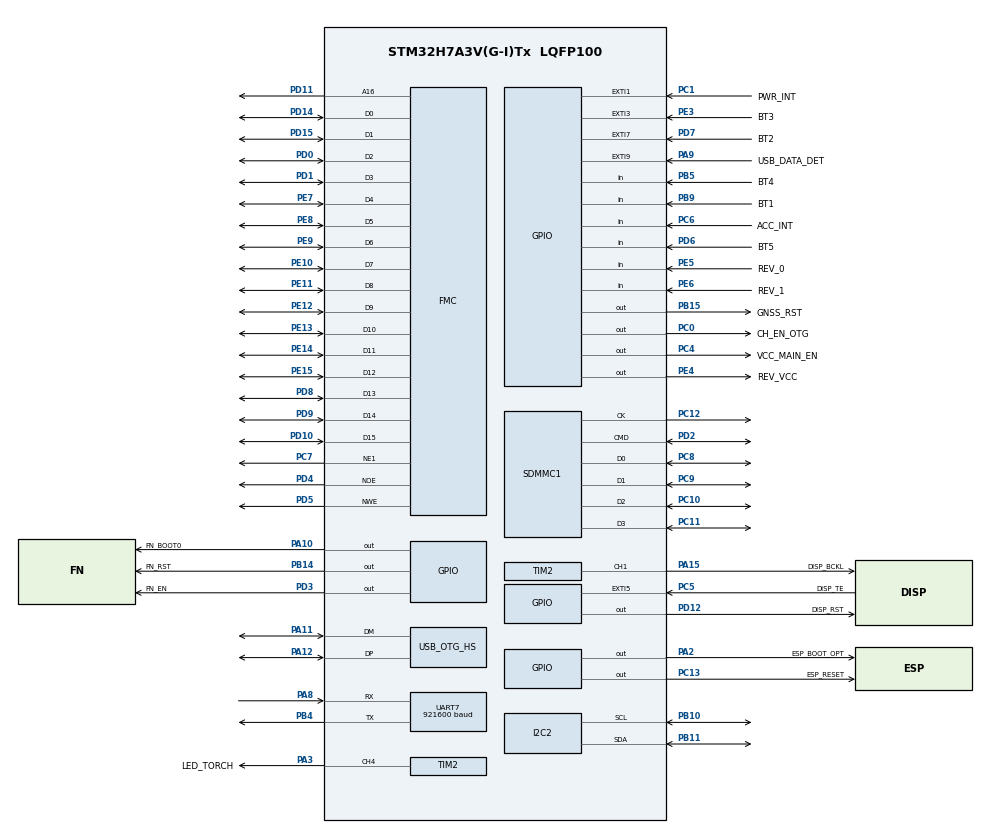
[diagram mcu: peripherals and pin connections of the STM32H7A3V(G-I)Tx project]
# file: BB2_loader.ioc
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CORTEX_M7.AccessPermission-Cortex_Memory_Protection_Unit_Region0_Settings=MPU_REGION_FULL_ACCESS
CORTEX_M7.CPU_DCache=Disabled
CORTEX_M7.Enable-Cortex_Memory_Protection_Unit_Region0_Settings=MPU_REGION_ENABLE
CORTEX_M7.MPU_Control=__NULL
CORTEX_M7.Size-Cortex_Memory_Protection_Unit_Region0_Settings=MPU_REGION_SIZE_4GB
CRC.InputDataInversionMode=CRC_INPUTDATA_INVERSION_BYTE
CRC.OutputDataInversionMode=CRC_OUTPUTDATA_INVERSION_ENABLE
Dma.MEMTOMEM.0.Direction=DMA_MEMORY_TO_MEMORY
Dma.MEMTOMEM.0.EventEnable=DISABLE
Dma.MEMTOMEM.0.FIFOMode=DMA_FIFOMODE_ENABLE
Dma.MEMTOMEM.0.FIFOThreshold=DMA_FIFO_THRESHOLD_FULL
Dma.MEMTOMEM.0.Instance=DMA1_Stream0
Dma.MEMTOMEM.0.MemBurst=DMA_MBURST_SINGLE
Dma.MEMTOMEM.0.MemDataAlignment=DMA_MDATAALIGN_WORD
Dma.MEMTOMEM.0.MemInc=DMA_MINC_DISABLE
Dma.MEMTOMEM.0.Mode=DMA_NORMAL
Dma.MEMTOMEM.0.PeriphBurst=DMA_PBURST_SINGLE
Dma.MEMTOMEM.0.PeriphDataAlignment=DMA_PDATAALIGN_WORD
Dma.MEMTOMEM.0.PeriphInc=DMA_PINC_ENABLE
Dma.MEMTOMEM.0.Polarity=HAL_DMAMUX_REQ_GEN_RISING
Dma.MEMTOMEM.0.Priority=DMA_PRIORITY_LOW
Dma.MEMTOMEM.0.RequestNumber=1
Dma.MEMTOMEM.0.SignalID=NONE
Dma.MEMTOMEM.0.SyncEnable=DISABLE
Dma.MEMTOMEM.0.SyncPolarity=HAL_DMAMUX_SYNC_NO_EVENT
Dma.MEMTOMEM.0.SyncRequestNumber=1
Dma.MEMTOMEM.0.SyncSignalID=NONE
Dma.Request0=MEMTOMEM
Dma.Request1=UART7_TX
Dma.UART7_TX.1.Direction=DMA_MEMORY_TO_PERIPH
Dma.UART7_TX.1.EventEnable=DISABLE
Dma.UART7_TX.1.FIFOMode=DMA_FIFOMODE_DISABLE
Dma.UART7_TX.1.Instance=DMA1_Stream1
Dma.UART7_TX.1.MemDataAlignment=DMA_MDATAALIGN_BYTE
Dma.UART7_TX.1.MemInc=DMA_MINC_ENABLE
Dma.UART7_TX.1.Mode=DMA_NORMAL
Dma.UART7_TX.1.PeriphDataAlignment=DMA_PDATAALIGN_BYTE
Dma.UART7_TX.1.PeriphInc=DMA_PINC_DISABLE
Dma.UART7_TX.1.Polarity=HAL_DMAMUX_REQ_GEN_RISING
Dma.UART7_TX.1.Priority=DMA_PRIORITY_MEDIUM
Dma.UART7_TX.1.RequestNumber=1
Dma.UART7_TX.1.SignalID=NONE
Dma.UART7_TX.1.SyncEnable=DISABLE
Dma.UART7_TX.1.SyncPolarity=HAL_DMAMUX_SYNC_NO_EVENT
Dma.UART7_TX.1.SyncRequestNumber=1
Dma.UART7_TX.1.SyncSignalID=NONE
FATFS.USE_DMA_CODE_SD=1
FATFS._USE_MKFS=0
FMC.AddressSetupTime1=6
FMC.BankMapConfig=FMC_SWAPBMAP_SDRAM_SRAM
FMC.BusTurnAroundDuration1=0
FMC.DataSetupTime1=12
I2C2.Timing=0x20B0CCFF
Mcu.Family=STM32H7
Mcu.Name=STM32H7A3V(G-I)Tx
Mcu.Package=LQFP100
Mcu.UserConstants=debug_uart,huart7;esp_uart,huart4;fanet_uart,huart8;gnss_uart,huart5;tft_dma,hdma_memtomem_dma1_stream0;led_timmer,htim2;led_bclk,TIM_CHANNEL_1;led_torch,TIM_CHANNEL_4;mems_i2c,hi2c1;sys_i2c,hi2c2;meas_timer,htim3
Mdma.MDMA_Channel0.Request0=SDMMC1_COMMAND_END
Mdma.MDMA_Channel0.Request1=SDMMC1_DMA_ENDBUFFER
Mdma.MDMA_Channel0.Request2=SDMMC1_END_DATA
Mdma.MDMA_Channel0.RequestsNb=3
Mdma.MDMA_Channel0.SDMMC1_COMMAND_END.0.BlockCount=0
Mdma.MDMA_Channel0.SDMMC1_COMMAND_END.0.BlockDataLength=0
Mdma.MDMA_Channel0.SDMMC1_COMMAND_END.0.BufferTransferLength=1
Mdma.MDMA_Channel0.SDMMC1_COMMAND_END.0.CircularMode=MDMA_LINEAR_LIST
Mdma.MDMA_Channel0.SDMMC1_COMMAND_END.0.DataAlignment=MDMA_DATAALIGN_PACKENABLE
Mdma.MDMA_Channel0.SDMMC1_COMMAND_END.0.DestBlockAddressOffset=0
Mdma.MDMA_Channel0.SDMMC1_COMMAND_END.0.DestBurst=MDMA_DEST_BURST_SINGLE
Mdma.MDMA_Channel0.SDMMC1_COMMAND_END.0.DestDataSize=MDMA_DEST_DATASIZE_BYTE
Mdma.MDMA_Channel0.SDMMC1_COMMAND_END.0.DestinationInc=MDMA_DEST_INC_BYTE
Mdma.MDMA_Channel0.SDMMC1_COMMAND_END.0.DstAddress=0
Mdma.MDMA_Channel0.SDMMC1_COMMAND_END.0.Endianness=MDMA_LITTLE_ENDIANNESS_PRESERVE
Mdma.MDMA_Channel0.SDMMC1_COMMAND_END.0.Instance=MDMA_Channel0
Mdma.MDMA_Channel0.SDMMC1_COMMAND_END.0.MaskAddress=0
Mdma.MDMA_Channel0.SDMMC1_COMMAND_END.0.MaskData=0
Mdma.MDMA_Channel0.SDMMC1_COMMAND_END.0.Priority=MDMA_PRIORITY_LOW
Mdma.MDMA_Channel0.SDMMC1_COMMAND_END.0.Rank=First
Mdma.MDMA_Channel0.SDMMC1_COMMAND_END.0.SourceBlockAddressOffset=0
Mdma.MDMA_Channel0.SDMMC1_COMMAND_END.0.SourceBurst=MDMA_SOURCE_BURST_SINGLE
Mdma.MDMA_Channel0.SDMMC1_COMMAND_END.0.SourceDataSize=MDMA_SRC_DATASIZE_BYTE
Mdma.MDMA_Channel0.SDMMC1_COMMAND_END.0.SourceInc=MDMA_SRC_INC_BYTE
Mdma.MDMA_Channel0.SDMMC1_COMMAND_END.0.SrcAddress=0
Mdma.MDMA_Channel0.SDMMC1_COMMAND_END.0.TransferTriggerMode=MDMA_BUFFER_TRANSFER
Mdma.MDMA_Channel0.SDMMC1_DMA_ENDBUFFER.1.BlockCount=0
Mdma.MDMA_Channel0.SDMMC1_DMA_ENDBUFFER.1.BlockDataLength=0
Mdma.MDMA_Channel0.SDMMC1_DMA_ENDBUFFER.1.BufferTransferLength=1
Mdma.MDMA_Channel0.SDMMC1_DMA_ENDBUFFER.1.CircularMode=MDMA_LINEAR_LIST
Mdma.MDMA_Channel0.SDMMC1_DMA_ENDBUFFER.1.DataAlignment=MDMA_DATAALIGN_PACKENABLE
Mdma.MDMA_Channel0.SDMMC1_DMA_ENDBUFFER.1.DestBlockAddressOffset=0
Mdma.MDMA_Channel0.SDMMC1_DMA_ENDBUFFER.1.DestBurst=MDMA_DEST_BURST_SINGLE
Mdma.MDMA_Channel0.SDMMC1_DMA_ENDBUFFER.1.DestDataSize=MDMA_DEST_DATASIZE_BYTE
Mdma.MDMA_Channel0.SDMMC1_DMA_ENDBUFFER.1.DestinationInc=MDMA_DEST_INC_BYTE
Mdma.MDMA_Channel0.SDMMC1_DMA_ENDBUFFER.1.DstAddress=0
Mdma.MDMA_Channel0.SDMMC1_DMA_ENDBUFFER.1.Endianness=MDMA_LITTLE_ENDIANNESS_PRESERVE
Mdma.MDMA_Channel0.SDMMC1_DMA_ENDBUFFER.1.Instance=MDMA_Channel0
Mdma.MDMA_Channel0.SDMMC1_DMA_ENDBUFFER.1.MaskAddress=0
Mdma.MDMA_Channel0.SDMMC1_DMA_ENDBUFFER.1.MaskData=0
Mdma.MDMA_Channel0.SDMMC1_DMA_ENDBUFFER.1.Priority=MDMA_PRIORITY_LOW
Mdma.MDMA_Channel0.SDMMC1_DMA_ENDBUFFER.1.Rank=Intermediate
Mdma.MDMA_Channel0.SDMMC1_DMA_ENDBUFFER.1.SourceBlockAddressOffset=0
Mdma.MDMA_Channel0.SDMMC1_DMA_ENDBUFFER.1.SourceBurst=MDMA_SOURCE_BURST_SINGLE
Mdma.MDMA_Channel0.SDMMC1_DMA_ENDBUFFER.1.SourceDataSize=MDMA_SRC_DATASIZE_BYTE
Mdma.MDMA_Channel0.SDMMC1_DMA_ENDBUFFER.1.SourceInc=MDMA_SRC_INC_BYTE
Mdma.MDMA_Channel0.SDMMC1_DMA_ENDBUFFER.1.SrcAddress=0
Mdma.MDMA_Channel0.SDMMC1_DMA_ENDBUFFER.1.TransferTriggerMode=MDMA_BUFFER_TRANSFER
Mdma.MDMA_Channel0.SDMMC1_DMA_ENDBUFFER.1.node=node_mdma_channel40_sdmmc1_dma_endbuffer_1
Mdma.MDMA_Channel0.SDMMC1_DMA_ENDBUFFER.1.pNewNode=node_mdma_channel40_sdmmc1_dma_endbuffer_1
Mdma.MDMA_Channel0.SDMMC1_END_DATA.2.BlockCount=0
Mdma.MDMA_Channel0.SDMMC1_END_DATA.2.BlockDataLength=0
Mdma.MDMA_Channel0.SDMMC1_END_DATA.2.BufferTransferLength=1
Mdma.MDMA_Channel0.SDMMC1_END_DATA.2.CircularMode=MDMA_LINEAR_LIST
Mdma.MDMA_Channel0.SDMMC1_END_DATA.2.DataAlignment=MDMA_DATAALIGN_PACKENABLE
Mdma.MDMA_Channel0.SDMMC1_END_DATA.2.DestBlockAddressOffset=0
Mdma.MDMA_Channel0.SDMMC1_END_DATA.2.DestBurst=MDMA_DEST_BURST_SINGLE
Mdma.MDMA_Channel0.SDMMC1_END_DATA.2.DestDataSize=MDMA_DEST_DATASIZE_BYTE
Mdma.MDMA_Channel0.SDMMC1_END_DATA.2.DestinationInc=MDMA_DEST_INC_BYTE
Mdma.MDMA_Channel0.SDMMC1_END_DATA.2.DstAddress=0
Mdma.MDMA_Channel0.SDMMC1_END_DATA.2.Endianness=MDMA_LITTLE_ENDIANNESS_PRESERVE
Mdma.MDMA_Channel0.SDMMC1_END_DATA.2.Instance=MDMA_Channel0
Mdma.MDMA_Channel0.SDMMC1_END_DATA.2.MaskAddress=0
Mdma.MDMA_Channel0.SDMMC1_END_DATA.2.MaskData=0
Mdma.MDMA_Channel0.SDMMC1_END_DATA.2.Priority=MDMA_PRIORITY_LOW
Mdma.MDMA_Channel0.SDMMC1_END_DATA.2.Rank=Last
Mdma.MDMA_Channel0.SDMMC1_END_DATA.2.SourceBlockAddressOffset=0
Mdma.MDMA_Channel0.SDMMC1_END_DATA.2.SourceBurst=MDMA_SOURCE_BURST_SINGLE
Mdma.MDMA_Channel0.SDMMC1_END_DATA.2.SourceDataSize=MDMA_SRC_DATASIZE_BYTE
Mdma.MDMA_Channel0.SDMMC1_END_DATA.2.SourceInc=MDMA_SRC_INC_BYTE
Mdma.MDMA_Channel0.SDMMC1_END_DATA.2.SrcAddress=0
Mdma.MDMA_Channel0.SDMMC1_END_DATA.2.TransferTriggerMode=MDMA_BUFFER_TRANSFER
Mdma.MDMA_Channel0.SDMMC1_END_DATA.2.node=node_mdma_channel40_sdmmc1_end_data_2
Mdma.MDMA_Channel0.SDMMC1_END_DATA.2.pNewNode=node_mdma_channel40_sdmmc1_end_data_2
Mdma.RequestSet0=MDMA_Channel0
Mdma.RequestSetsNb=1
NVIC.DMA1_Stream0_IRQn=true\:5\:0\:true\:false\:true\:true\:true
NVIC.DMA1_Stream1_IRQn=true\:5\:0\:true\:false\:true\:false\:true
NVIC.EXTI1_IRQn=true\:0\:0\:false\:false\:true\:true\:true
NVIC.EXTI3_IRQn=true\:0\:0\:false\:false\:true\:true\:true
NVIC.EXTI9_5_IRQn=true\:5\:0\:true\:false\:true\:true\:true
NVIC.OTG_HS_IRQn=true\:6\:0\:true\:false\:true\:false\:true
NVIC.PriorityGroup=NVIC_PRIORITYGROUP_4
NVIC.SDMMC1_IRQn=true\:5\:0\:true\:false\:true\:true\:true
NVIC.TIM1_UP_IRQn=true\:0\:0\:true\:false\:true\:false\:true
NVIC.TimeBase=TIM1_UP_IRQn
NVIC.TimeBaseIP=TIM1
NVIC.UART7_IRQn=true\:5\:0\:true\:false\:true\:true\:true
PA0.Signal=UART4_TX
PA10.GPIO_Label=FN_BOOT0
PA10.Signal=GPIO_Output
PA11.GPIO_Speed=GPIO_SPEED_FREQ_VERY_HIGH
PA11.Mode=Device_Only_FS
PA11.Signal=USB_OTG_HS_DM
PA12.GPIO_Speed=GPIO_SPEED_FREQ_VERY_HIGH
PA12.Mode=Device_Only_FS
PA12.Signal=USB_OTG_HS_DP
PA13.Mode=Trace_Asynchronous_SW
PA13.Signal=DEBUG_JTMS-SWDIO
PA14.Mode=Trace_Asynchronous_SW
PA14.Signal=DEBUG_JTCK-SWCLK
PA15.GPIO_Label=DISP_BCKL
PA15.Signal=S_TIM2_CH1
PA2.GPIO_Label=ESP_BOOT_OPT
PA2.Signal=GPIO_Output
PA3.GPIO_Label=LED_TORCH
PA3.Signal=S_TIM2_CH4
PA8.Mode=Asynchronous
PA8.Signal=UART7_RX
PA9.GPIO_Label=USB_DATA_DET
PA9.GPIO_PuPd=GPIO_PULLDOWN
PA9.Signal=GPXTI9
PB10.Mode=I2C
PB10.Signal=I2C2_SCL
PB11.Mode=I2C
PB11.Signal=I2C2_SDA
PB14.GPIO_Label=FN_RST
PB14.Signal=GPIO_Output
PB15.GPIO_Label=GNSS_RST
PB15.Signal=GPIO_Output
PB2.Signal=OCTOSPIM_P1_CLK
PB3.Mode=Trace_Asynchronous_SW
PB3.Signal=DEBUG_JTDO-SWO
PB4.Mode=Asynchronous
PB4.Signal=UART7_TX
PB5.GPIO_Label=BT4
PB5.Signal=GPIO_Input
PB9.GPIO_Label=BT1
PB9.Signal=GPIO_Input
PC0.GPIO_Label=CH_EN_OTG
PC0.Signal=GPIO_Output
PC1.GPIO_Label=PWR_INT
PC1.Signal=GPXTI1
PC10.Mode=SD_4_bits_Wide_bus
PC10.Signal=SDMMC1_D2
PC11.Mode=SD_4_bits_Wide_bus
PC11.Signal=SDMMC1_D3
PC12.Mode=SD_4_bits_Wide_bus
PC12.Signal=SDMMC1_CK
PC13.GPIO_Label=ESP_RESET
PC13.Signal=GPIO_Output
PC14-OSC32_IN.Mode=LSE-External-Oscillator
PC14-OSC32_IN.Signal=RCC_OSC32_IN
PC15-OSC32_OUT.Mode=LSE-External-Oscillator
PC15-OSC32_OUT.Signal=RCC_OSC32_OUT
PC4.GPIO_Label=VCC_MAIN_EN
PC4.Signal=GPIO_Output
PC5.GPIO_Label=DISP_TE
PC5.Signal=GPXTI5
PC6.GPIO_Label=ACC_INT
PC6.Signal=GPIO_Input
PC7.Mode=NorPsramChipSelect1_1
PC7.Signal=FMC_NE1
PC8.Mode=SD_4_bits_Wide_bus
PC8.Signal=SDMMC1_D0
PC9.Mode=SD_4_bits_Wide_bus
PC9.Signal=SDMMC1_D1
PD0.Signal=FMC_D2_DA2
PD1.Signal=FMC_D3_DA3
PD10.Signal=FMC_D15_DA15
PD11.Signal=FMC_A16_CLE
PD12.GPIO_Label=DISP_RST
PD12.Signal=GPIO_Output
PD14.Signal=FMC_D0_DA0
PD15.Signal=FMC_D1_DA1
PD2.Mode=SD_4_bits_Wide_bus
PD2.Signal=SDMMC1_CMD
PD3.GPIO_Label=FN_EN
PD3.Signal=GPIO_Output
PD4.Signal=FMC_NOE
PD5.Signal=FMC_NWE
PD6.GPIO_Label=BT5
PD6.Signal=GPIO_Input
PD7.GPIO_Label=BT2
PD7.GPIO_ModeDefaultEXTI=GPIO_MODE_IT_FALLING
PD7.Signal=GPXTI7
PD8.Signal=FMC_D13_DA13
PD9.Signal=FMC_D14_DA14
PE10.Signal=FMC_D7_DA7
PE11.Signal=FMC_D8_DA8
PE12.Signal=FMC_D9_DA9
PE13.Signal=FMC_D10_DA10
PE14.Signal=FMC_D11_DA11
PE15.Signal=FMC_D12_DA12
PE3.GPIO_Label=BT3
PE3.GPIO_ModeDefaultEXTI=GPIO_MODE_IT_FALLING
PE3.Signal=GPXTI3
PE4.GPIO_Label=REV_VCC
PE4.Signal=GPIO_Output
PE5.GPIO_Label=REV_0
PE5.Signal=GPIO_Input
PE6.GPIO_Label=REV_1
PE6.Signal=GPIO_Input
PE7.Signal=FMC_D4_DA4
PE8.Signal=FMC_D5_DA5
PE9.Signal=FMC_D6_DA6
PH0-OSC_IN.Mode=HSE-External-Oscillator
PH0-OSC_IN.Signal=RCC_OSC_IN
PH1-OSC_OUT.Mode=HSE-External-Oscillator
PH1-OSC_OUT.Signal=RCC_OSC_OUT
ProjectManager.HeapSize=0x400
ProjectManager.StackSize=0x800
ProjectManager.TargetToolchain=STM32CubeIDE
RCC.ADCFreq_Value=72000000
RCC.APB1Freq_Value=140000000
RCC.APB2Freq_Value=140000000
RCC.APB3Freq_Value=140000000
RCC.APB4Freq_Value=140000000
RCC.CDPPRE=RCC_APB3_DIV2
RCC.CDPPRE1=RCC_APB1_DIV2
RCC.CDPPRE2=RCC_APB2_DIV2
RCC.CortexFreq_Value=280000000
RCC.DIVM1=1
RCC.DIVM2=1
RCC.DIVM3=1
RCC.DIVN1=70
RCC.DIVN2=18
RCC.DIVN3=18
RCC.DIVP3=4
RCC.DIVQ3=3
RCC.DIVR2=4
RCC.DIVR3=3
RCC.HCLKFreq_Value=280000000
RCC.HSE_VALUE=8000000
RCC.LSE_Drive_Capability=RCC_LSEDRIVE_HIGH
RCC.PLL2FRACN=0
RCC.PLL3FRACN=0
RCC.PLLFRACN=0
RCC.PLLSourceVirtual=RCC_PLLSOURCE_HSE
RCC.QSPICLockSelection=RCC_OSPICLKSOURCE_PLL2
RCC.RTCClockSelection=RCC_RTCCLKSOURCE_LSE
RCC.SDMMC1CLockSelection=RCC_SDMMCCLKSOURCE_PLL2
RCC.SRDPPRE=RCC_APB4_DIV2
RCC.SYSCLKFreq_VALUE=280000000
RCC.SYSCLKSource=RCC_SYSCLKSOURCE_PLLCLK
RCC.USBCLockSelection=RCC_USBCLKSOURCE_PLL3
RCC.USBFreq_Value=48000000
RCC.VDD_VALUE=3
RTC.Format=RTC_FORMAT_BIN
SDMMC1.ClockDiv=0
SDMMC1.ClockEdge=SDMMC_CLOCK_EDGE_RISING
SDMMC1.ClockPowerSave=SDMMC_CLOCK_POWER_SAVE_DISABLE
SDMMC1.HardwareFlowControl=SDMMC_HARDWARE_FLOW_CONTROL_DISABLE
SH.FMC_A16_CLE.0=FMC_A16,A16_1
SH.FMC_D0_DA0.0=FMC_D0,16b-d1
SH.FMC_D10_DA10.0=FMC_D10,16b-d1
SH.FMC_D11_DA11.0=FMC_D11,16b-d1
SH.FMC_D12_DA12.0=FMC_D12,16b-d1
SH.FMC_D13_DA13.0=FMC_D13,16b-d1
SH.FMC_D14_DA14.0=FMC_D14,16b-d1
SH.FMC_D15_DA15.0=FMC_D15,16b-d1
SH.FMC_D1_DA1.0=FMC_D1,16b-d1
SH.FMC_D2_DA2.0=FMC_D2,16b-d1
SH.FMC_D3_DA3.0=FMC_D3,16b-d1
SH.FMC_D4_DA4.0=FMC_D4,16b-d1
SH.FMC_D5_DA5.0=FMC_D5,16b-d1
SH.FMC_D6_DA6.0=FMC_D6,16b-d1
SH.FMC_D7_DA7.0=FMC_D7,16b-d1
SH.FMC_D8_DA8.0=FMC_D8,16b-d1
SH.FMC_D9_DA9.0=FMC_D9,16b-d1
SH.FMC_NOE.0=FMC_NOE,Lcd1
SH.FMC_NWE.0=FMC_NWE,Lcd1
SH.S_TIM2_CH1.0=TIM2_CH1,PWM Generation1 CH1
SH.S_TIM2_CH4.0=TIM2_CH4,PWM Generation4 CH4
TIM2.Channel-PWM\ Generation1\ CH1=TIM_CHANNEL_1
TIM2.Channel-PWM\ Generation4\ CH4=TIM_CHANNEL_4
TIM2.Period=100
TIM2.Prescaler=16
UART7.BaudRate=921600
USB_DEVICE.CLASS_NAME_HS=MSC
USB_DEVICE.MANUFACTURER_STRING-MSC_HS=SkyBean
USB_DEVICE.MSC_MEDIA_PACKET-MSC_HS=4096
USB_DEVICE.PRODUCT_STRING_MSC_HS=BoomBox
USB_DEVICE.USBD_DEBUG_LEVEL-MSC_HS=0
USB_DEVICE.USBD_SELF_POWERED-MSC_HS=1
USB_DEVICE.VirtualMode-MSC_HS=Msc
USB_DEVICE.VirtualModeHS=Msc_HS
USB_OTG_HS.VirtualMode=Device_Only_FS
USB_OTG_HS.dma_enable=DISABLE
USB_OTG_HS.lpm_enable=DISABLE
USB_OTG_HS.use_dedicated_ep1=DISABLE
VP_CRC_VS_CRC.Mode=CRC_Activate
VP_FATFS_VS_SDIO.Mode=SDIO
VP_RTC_VS_RTC_Activate.Mode=RTC_Enabled
VP_RTC_VS_RTC_Calendar.Mode=RTC_Calendar
VP_SYS_VS_tim1.Mode=TIM1
VP_USB_DEVICE_VS_USB_DEVICE_MSC_HS.Mode=MSC_HS
board=custom

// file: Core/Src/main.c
/* USER CODE BEGIN Header */
/**
  ******************************************************************************
  * @file           : main.c
  * @brief          : Main program body
  ******************************************************************************
  * @attention
  *
  * <h2><center>&copy; Copyright (c) 2020 STMicroelectronics.
  * All rights reserved.</center></h2>
  *
  * This software component is licensed by ST under Ultimate Liberty license
  * SLA0044, the "License"; You may not use this file except in compliance with
  * the License. You may obtain a copy of the License at:
  *                             www.st.com/SLA0044
  *
  ******************************************************************************
  */
/* USER CODE END Header */
#include "main.h"
#include "crc.h"
#include "dma.h"
#include "fatfs.h"
#include "i2c.h"
#include "mdma.h"
#include "rtc.h"
#include "sdmmc.h"
#include "tim.h"
#include "usart.h"
#include "usb_device.h"
#include "gpio.h"
#include "fmc.h"

void SystemClock_Config(void);
/* USER CODE BEGIN PFP */
void app_main(uint8_t power_on_mode);
uint8_t app_poweroff();
/* USER CODE END PFP */

int main(void)
{

  /* MCU Configuration--------------------------------------------------------*/

  /* Reset of all peripherals, Initializes the Flash interface and the Systick. */
  HAL_Init();

  /* USER CODE BEGIN Init */
  uint8_t power_on_mode = app_poweroff();
  /* USER CODE END Init */

  /* Configure the system clock */
  SystemClock_Config();

  /* Initialize all configured peripherals */
  MX_GPIO_Init();
  MX_DMA_Init();
  MX_MDMA_Init();
  MX_FMC_Init();
  MX_SDMMC1_SD_Init();
  MX_TIM2_Init();
  MX_UART7_Init();
  MX_FATFS_Init();
  MX_CRC_Init();
  MX_RTC_Init();
  MX_I2C2_Init();
  /* USER CODE BEGIN 2 */
  app_main(power_on_mode);
  /* USER CODE END 2 */

  /* Infinite loop */
  while (1)
  {

  }
}

void SystemClock_Config(void)
{
  RCC_OscInitTypeDef RCC_OscInitStruct = {0};
  RCC_ClkInitTypeDef RCC_ClkInitStruct = {0};
  RCC_PeriphCLKInitTypeDef PeriphClkInitStruct = {0};

  /** Supply configuration update enable
  */
  HAL_PWREx_ConfigSupply(PWR_LDO_SUPPLY);
  /** Configure the main internal regulator output voltage
  */
  __HAL_PWR_VOLTAGESCALING_CONFIG(PWR_REGULATOR_VOLTAGE_SCALE0);

  while(!__HAL_PWR_GET_FLAG(PWR_FLAG_VOSRDY)) {}
  /** Configure LSE Drive Capability
  */
  HAL_PWR_EnableBkUpAccess();
  __HAL_RCC_LSEDRIVE_CONFIG(RCC_LSEDRIVE_HIGH);
  /** Macro to configure the PLL clock source
  */
  __HAL_RCC_PLL_PLLSOURCE_CONFIG(RCC_PLLSOURCE_HSE);
  /** Initializes the RCC Oscillators according to the specified parameters
  * in the RCC_OscInitTypeDef structure.
  */
  RCC_OscInitStruct.OscillatorType = RCC_OSCILLATORTYPE_HSE|RCC_OSCILLATORTYPE_LSE;
  RCC_OscInitStruct.HSEState = RCC_HSE_ON;
  RCC_OscInitStruct.LSEState = RCC_LSE_ON;
  RCC_OscInitStruct.PLL.PLLState = RCC_PLL_ON;
  RCC_OscInitStruct.PLL.PLLSource = RCC_PLLSOURCE_HSE;
  RCC_OscInitStruct.PLL.PLLM = 1;
  RCC_OscInitStruct.PLL.PLLN = 70;
  RCC_OscInitStruct.PLL.PLLP = 2;
  RCC_OscInitStruct.PLL.PLLQ = 2;
  RCC_OscInitStruct.PLL.PLLR = 2;
  RCC_OscInitStruct.PLL.PLLRGE = RCC_PLL1VCIRANGE_3;
  RCC_OscInitStruct.PLL.PLLVCOSEL = RCC_PLL1VCOWIDE;
  RCC_OscInitStruct.PLL.PLLFRACN = 0;
  if (HAL_RCC_OscConfig(&RCC_OscInitStruct) != HAL_OK)
  {
    Error_Handler();
  }
  /** Initializes the CPU, AHB and APB buses clocks
  */
  RCC_ClkInitStruct.ClockType = RCC_CLOCKTYPE_HCLK|RCC_CLOCKTYPE_SYSCLK
                              |RCC_CLOCKTYPE_PCLK1|RCC_CLOCKTYPE_PCLK2
                              |RCC_CLOCKTYPE_D3PCLK1|RCC_CLOCKTYPE_D1PCLK1;
  RCC_ClkInitStruct.SYSCLKSource = RCC_SYSCLKSOURCE_PLLCLK;
  RCC_ClkInitStruct.SYSCLKDivider = RCC_SYSCLK_DIV1;
  RCC_ClkInitStruct.AHBCLKDivider = RCC_HCLK_DIV1;
  RCC_ClkInitStruct.APB3CLKDivider = RCC_APB3_DIV2;
  RCC_ClkInitStruct.APB1CLKDivider = RCC_APB1_DIV2;
  RCC_ClkInitStruct.APB2CLKDivider = RCC_APB2_DIV2;
  RCC_ClkInitStruct.APB4CLKDivider = RCC_APB4_DIV2;

  if (HAL_RCC_ClockConfig(&RCC_ClkInitStruct, FLASH_LATENCY_7) != HAL_OK)
  {
    Error_Handler();
  }
  PeriphClkInitStruct.PeriphClockSelection = RCC_PERIPHCLK_RTC|RCC_PERIPHCLK_UART7
                              |RCC_PERIPHCLK_SDMMC|RCC_PERIPHCLK_I2C2
                              |RCC_PERIPHCLK_USB|RCC_PERIPHCLK_FMC;
  PeriphClkInitStruct.PLL2.PLL2M = 1;
  PeriphClkInitStruct.PLL2.PLL2N = 18;
  PeriphClkInitStruct.PLL2.PLL2P = 2;
  PeriphClkInitStruct.PLL2.PLL2Q = 2;
  PeriphClkInitStruct.PLL2.PLL2R = 4;
  PeriphClkInitStruct.PLL2.PLL2RGE = RCC_PLL2VCIRANGE_3;
  PeriphClkInitStruct.PLL2.PLL2VCOSEL = RCC_PLL2VCOWIDE;
  PeriphClkInitStruct.PLL2.PLL2FRACN = 0;
  PeriphClkInitStruct.PLL3.PLL3M = 1;
  PeriphClkInitStruct.PLL3.PLL3N = 18;
  PeriphClkInitStruct.PLL3.PLL3P = 4;
  PeriphClkInitStruct.PLL3.PLL3Q = 3;
  PeriphClkInitStruct.PLL3.PLL3R = 3;
  PeriphClkInitStruct.PLL3.PLL3RGE = RCC_PLL3VCIRANGE_3;
  PeriphClkInitStruct.PLL3.PLL3VCOSEL = RCC_PLL3VCOWIDE;
  PeriphClkInitStruct.PLL3.PLL3FRACN = 0;
  PeriphClkInitStruct.FmcClockSelection = RCC_FMCCLKSOURCE_D1HCLK;
  PeriphClkInitStruct.SdmmcClockSelection = RCC_SDMMCCLKSOURCE_PLL2;
  PeriphClkInitStruct.Usart234578ClockSelection = RCC_USART234578CLKSOURCE_D2PCLK1;
  PeriphClkInitStruct.I2c123ClockSelection = RCC_I2C123CLKSOURCE_D2PCLK1;
  PeriphClkInitStruct.UsbClockSelection = RCC_USBCLKSOURCE_PLL3;
  PeriphClkInitStruct.RTCClockSelection = RCC_RTCCLKSOURCE_LSE;
  if (HAL_RCCEx_PeriphCLKConfig(&PeriphClkInitStruct) != HAL_OK)
  {
    Error_Handler();
  }
}

void HAL_TIM_PeriodElapsedCallback(TIM_HandleTypeDef *htim)
{
  if (htim->Instance == TIM1) {
    HAL_IncTick();
  }
}

void Error_Handler(void)
{
  /* USER CODE BEGIN Error_Handler_Debug */
  /* User can add his own implementation to report the HAL error return state */
	while(1);
  /* USER CODE END Error_Handler_Debug */
}

/************************ (C) COPYRIGHT STMicroelectronics *****END OF FILE****/
